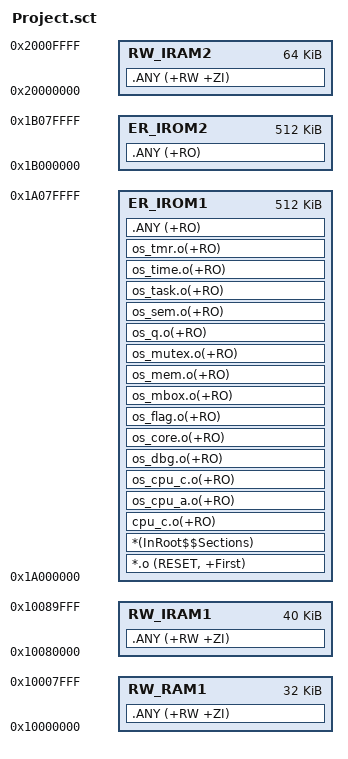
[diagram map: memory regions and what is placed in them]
; *************************************************************
; *** Scatter-Loading Description File generated by uVision ***
; *************************************************************

LR_IROM1 0x1A000000 0x00080000  {    ; load region size_region
  ER_IROM1 0x1A000000 0x00080000  {  ; load address = execution address
   *.o (RESET, +First)
   *(InRoot$$Sections)
    cpu_c.o(+RO) 
    os_cpu_a.o(+RO) 
    os_cpu_c.o(+RO) 
    os_dbg.o(+RO) 
    os_core.o(+RO) 
    os_flag.o(+RO)
    os_mbox.o(+RO)
    os_mem.o(+RO)
    os_mutex.o(+RO)
    os_q.o(+RO) 
    os_sem.o(+RO) 
    os_task.o(+RO)
    os_time.o(+RO) 
    os_tmr.o(+RO) 

   .ANY (+RO)
  }
  RW_RAM1 0x10000000 0x00008000  {  ; RW data
   .ANY (+RW +ZI)
  }
  RW_IRAM1 0x10080000 0x0000A000  {
   .ANY (+RW +ZI)
  }
  RW_IRAM2 0x20000000 0x00010000  {
   .ANY (+RW +ZI)
  }
}

LR_IROM2 0x1B000000 0x00080000  {
  ER_IROM2 0x1B000000 0x00080000  {  ; load address = execution address

   .ANY (+RO)
  }
}

;LR_ROM1 0x14000000 0x02000000  {
;  ER_ROM1 0x14000000 0x02000000  {  ; load address = execution address
;
;   .ANY (+RO)
;  }
;}
